AUTOSAR XML (schema 314)
package /ComponentType
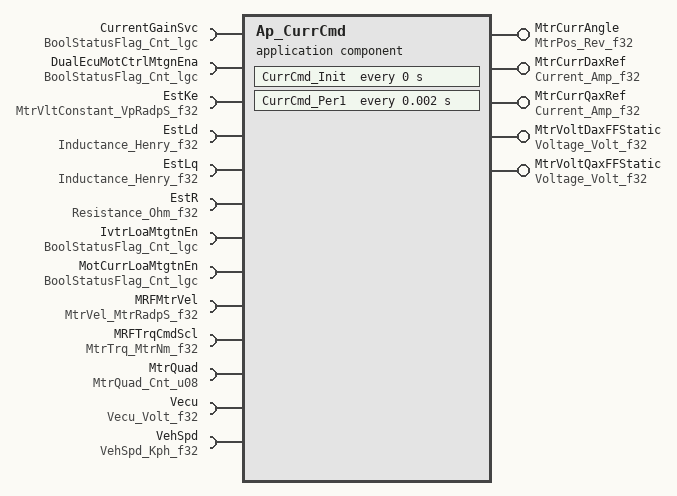
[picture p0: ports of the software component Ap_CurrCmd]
  application software component type Ap_CurrCmd  # Generates the Current Command and the Voltage Reference for the Current Control
    5 x provide port:
      MtrCurrAngle: unqueued-sender-com-spec{data-element=Rev_f32, can-invalidate=false, init-value=D_ZERO_ULS_F32}, provided-interface=MtrPos_Rev_f32
      MtrCurrDaxRef: unqueued-sender-com-spec{data-element=Amp_f32, can-invalidate=false, init-value=D_ZERO_ULS_F32}, provided-interface=Current_Amp_f32
      MtrCurrQaxRef: unqueued-sender-com-spec{data-element=Amp_f32, can-invalidate=false, init-value=D_ZERO_ULS_F32}, provided-interface=Current_Amp_f32
      MtrVoltDaxFFStatic: unqueued-sender-com-spec{data-element=Volt_f32, can-invalidate=false, init-value=D_ZERO_ULS_F32}, provided-interface=Voltage_Volt_f32
      MtrVoltQaxFFStatic: unqueued-sender-com-spec{data-element=Volt_f32, can-invalidate=false, init-value=D_ZERO_ULS_F32}, provided-interface=Voltage_Volt_f32
    13 x require port:
      CurrentGainSvc: unqueued-receiver-com-spec{data-element=Cnt_lgc, init-value=D_FALSE_CNT_LGC}, required-interface=BoolStatusFlag_Cnt_lgc
      DualEcuMotCtrlMtgnEna: unqueued-receiver-com-spec{data-element=Cnt_lgc, init-value=D_FALSE_CNT_LGC}, required-interface=BoolStatusFlag_Cnt_lgc
      EstKe: unqueued-receiver-com-spec{data-element=VpRadpS_f32, init-value=D_ZERO_ULS_F32}, required-interface=MtrVltConstant_VpRadpS_f32
      EstLd: unqueued-receiver-com-spec{data-element=Henry_f32, init-value=D_ZERO_ULS_F32}, required-interface=Inductance_Henry_f32
      EstLq: unqueued-receiver-com-spec{data-element=Henry_f32, init-value=D_ZERO_ULS_F32}, required-interface=Inductance_Henry_f32
      EstR: unqueued-receiver-com-spec{data-element=Ohm_f32, init-value=D_ZERO_ULS_F32}, required-interface=Resistance_Ohm_f32
      IvtrLoaMtgtnEn: unqueued-receiver-com-spec{data-element=Cnt_lgc, init-value=D_FALSE_CNT_LGC}, required-interface=BoolStatusFlag_Cnt_lgc
      MotCurrLoaMtgtnEn: unqueued-receiver-com-spec{data-element=Cnt_lgc, init-value=D_FALSE_CNT_LGC}, required-interface=BoolStatusFlag_Cnt_lgc
      MRFMtrVel: unqueued-receiver-com-spec{data-element=MtrRadpS_f32, init-value=D_ZERO_ULS_F32}, required-interface=MtrVel_MtrRadpS_f32
      MRFTrqCmdScl: unqueued-receiver-com-spec{data-element=MtrNm_f32, init-value=D_ZERO_ULS_F32}, required-interface=MtrTrq_MtrNm_f32
      MtrQuad: unqueued-receiver-com-spec{data-element=Cnt_u08, init-value=D_QUADRANT1_CNT_U8}, required-interface=MtrQuad_Cnt_u08
      Vecu: unqueued-receiver-com-spec{data-element=Volt_f32, init-value=D_VECUMIN_VOLTS_F32}, required-interface=Vecu_Volt_f32
      VehSpd: unqueued-receiver-com-spec{data-element=Kph_f32, init-value=D_ZERO_ULS_F32}, required-interface=VehSpd_Kph_f32
  internal behavior Ap_CurrCmd_InternalBehavior: component=Ap_CurrCmd
    timing event CurrCmd_InitEvent: start-on-event=CurrCmd_Init, period=0
    timing event TMT_CurrCmd_Per1: start-on-event=CurrCmd_Per1, period=0.002
    port-api-options:
      enable-take-address=false, indirect-api=false, port=CurrentGainSvc
      enable-take-address=false, indirect-api=false, port=DualEcuMotCtrlMtgnEna
      enable-take-address=false, indirect-api=false, port=EstKe
      enable-take-address=false, indirect-api=false, port=EstLd
      enable-take-address=false, indirect-api=false, port=EstLq
      enable-take-address=false, indirect-api=false, port=EstR
      enable-take-address=false, indirect-api=false, port=IvtrLoaMtgtnEn
      enable-take-address=false, indirect-api=false, port=MotCurrLoaMtgtnEn
      enable-take-address=false, indirect-api=false, port=MRFMtrVel
      enable-take-address=false, indirect-api=false, port=MRFTrqCmdScl
      enable-take-address=false, indirect-api=false, port=MtrCurrAngle
      enable-take-address=false, indirect-api=false, port=MtrCurrDaxRef
      enable-take-address=false, indirect-api=false, port=MtrCurrQaxRef
      enable-take-address=false, indirect-api=false, port=MtrQuad
      enable-take-address=false, indirect-api=false, port=MtrVoltDaxFFStatic
      enable-take-address=false, indirect-api=false, port=MtrVoltQaxFFStatic
      enable-take-address=false, indirect-api=false, port=Vecu
      enable-take-address=false, indirect-api=false, port=VehSpd
    runnable CurrCmd_Init
    runnable CurrCmd_Per1
      13 x data read access:
        READ_CurrentGainSvc_Cnt_lgc: data-element=CurrentGainSvc.Cnt_lgc
        READ_DualEcuMotCtrlMtgnEna_Cnt_lgc: data-element=DualEcuMotCtrlMtgnEna.Cnt_lgc
        READ_EstKe_VpRadpS_f32: data-element=EstKe.VpRadpS_f32
        READ_EstLd_Henry_f32: data-element=EstLd.Henry_f32
        READ_EstLq_Henry_f32: data-element=EstLq.Henry_f32
        READ_EstR_Ohm_f32: data-element=EstR.Ohm_f32
        READ_IvtrLoaMtgtnEn_Cnt_lgc: data-element=IvtrLoaMtgtnEn.Cnt_lgc
        READ_MotCurrLoaMtgtnEn_Cnt_lgc: data-element=MotCurrLoaMtgtnEn.Cnt_lgc
        READ_MRFMtrVel_MtrRadpS_f32: data-element=MRFMtrVel.MtrRadpS_f32
        READ_MRFTrqCmdScl_MtrNm_f32: data-element=MRFTrqCmdScl.MtrNm_f32
        READ_MtrQuad_Cnt_u08: data-element=MtrQuad.Cnt_u08
        READ_Vecu_Volt_f32: data-element=Vecu.Volt_f32
        READ_VehSpd_Kph_f32: data-element=VehSpd.Kph_f32
      5 x data write access:
        WRITE_MtrCurrAngle_Rev_f32: data-element=MtrCurrAngle.Rev_f32
        WRITE_MtrCurrDaxRef_Amp_f32: data-element=MtrCurrDaxRef.Amp_f32
        WRITE_MtrCurrQaxRef_Amp_f32: data-element=MtrCurrQaxRef.Amp_f32
        WRITE_MtrVoltDaxFFStatic_Volt_f32: data-element=MtrVoltDaxFFStatic.Volt_f32
        WRITE_MtrVoltQaxFFStatic_Volt_f32: data-element=MtrVoltQaxFFStatic.Volt_f32
  swc implementation Ap_CurrCmd_Implementation: behavior=Ap_CurrCmd_InternalBehavior
    code-descriptors:
      code Code: type=SRC
